# PAC52XX register map
Vendor: Active-Semi; Series: PAC52XX; File version: 1.0
CPU: CM0 r0p0, little endian, no MPU, no FPU, vendor SysTick, 2 interrupt priority bits
Registers are 32-bit, read-write, reset 0x0 unless marked. A register's access mark holds for its fields unless they carry their own. Offsets are from the block's base; [hi:lo] are bit positions; {n}, {i} and the like mark numbered series; 'fields as' and 'values as' point back to an identical list.

## ADC — Analog to Digital Converter
Base 0x40150000
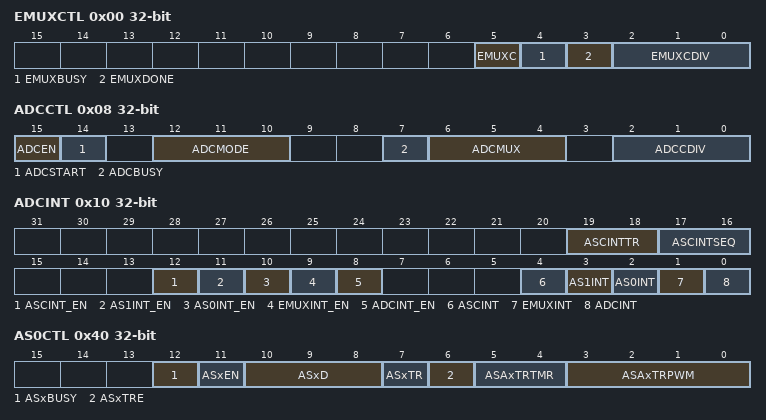
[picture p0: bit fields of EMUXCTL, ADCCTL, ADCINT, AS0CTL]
0x00 EMUXCTL — ADC External MUX control register
  [5] EMUXC — ADC External MUX control
    0=manual (ADC External MUX manual control); 1=auto (ADC External MUX controlled by auto-sequencer unit)
  [4] EMUXBUSY — ADC External MUX status
    0=busy (ADC External MUX busy); 1=not busy (ADC External MUX not busy)
  [3] EMUXDONE — ADC External MUX data send done
    0=busy (ADC External MUX busy); 1=data sent (ADC External MUX data sent)
  [2:0] EMUXCDIV — ADC External MUX clock to FCLK divider
    {v}=FCLK /{v+1} (FCLK dvided by {v+1}) (v=0..7)
0x04 EMUXDATA — ADC External MUX data register
  [15:0] DATA
0x08 ADCCTL — ADC control register
  [15] ADCEN — ADC Module Enable
    0=disabled (turn off ADC module); 1=enabled (enable ADC module)
  [14] ADCSTART — Start ADC Conversion
    0=stop ADC conversion; 1=start ADC conversion
  [12:10] ADCMODE — ADC conversion mode
    0=single channel; 1=AUTO0 (automated sequence 0 only); 2=AUTO1 (automated sequencer 1 only); 3=AUTO01 (automated sequencer 0 and 1 daisy chained); 4=AUTO0TRIG (automated sequencer 0 only trigger condition); 5=AUTO1TRIG (automated sequencer 1 only trigger condition); 6=AUTO01TRIG (automated sequencer 0 and 1 daisy chained trigger); 7=AUTO01TRIGIND (automated sequencer 0 and 1 independently triggered)
  [7] ADCBUSY ro
    0=no operation (ADC not busy); 1=busy (ADC conversion or auto sequencer active)
  [6:4] ADCMUX — ADC MUX input select
    0=AD0 (AD0 input); {v}=AD{v} (AD{v} input) (v=2..5); 7=VSSA (VSSA input)
  [2:0] ADCCDIV — ADC input clock FCLK divider
    {v}=FCLK /{v+1} (FCLK divided by {v+1}) (v=0..7)
0x0C ADCCR ro — ADC conversion result register
  [15:0] ADCRESULT — ADC conversion result
0x10 ADCINT — ADC interrupt register
  [19:18] ASCINTTR — Last auto sequencer to run
    0=none (no sequencer ran); 1=AS0 (auto sequencer 0 last ran); 2=AS1 (Auto sequencer 1 last ran)
  [17:16] ASCINTSEQ — Last auto sequencer to trigger ADCINT.ASCINT
    0=none (no trigger); 1=AS0 (auto sequencer 0 triggered interrupt); 2=AS1 (Auto sequencer 1 triggered interrupt); 3=Both auto sequencer 0 and 1 triggered interrupt
  [12] ASCINT_EN — Enable auto sequencer collision interrupt
    0=disabled (interrupt disabled); 1=enabled (interrupt enabled)
  [11] AS1INT_EN — Enable auto sequencer 1 conversions finished interrupt
    values as ASCINT_EN
  [10] AS0INT_EN — Enable auto sequencer 0 conversions finished interrupt
    values as ASCINT_EN
  [9] EMUXINT_EN — EMUX transfer finished interrupt enabled
    values as ASCINT_EN
  [8] ADCINT_EN — ADC conversion finished interrupt enabled
    values as ASCINT_EN
  [4] ASCINT — Auto sequencer collision interrupt
    0=none (no interrupt); 1=interrupt, write 1b to clear
  [3] AS1INT — Auto sequencer 1 conversions finished interrupt
    0=none (no interrupt); 1=interrupt, write 1b to clear
  [2] AS0INT — Auto sequencer 0 conversions finished interrupt
    0=none (no interrupt); 1=interrupt, write 1b to clear
  [1] EMUXINT — EMUX data transfer finished interrupt
    0=none (no interrupt); 1=interrupt, write 1b to clear
  [0] ADCINT — ADC conversion finished interrupt
    0=none (no interrupt); 1=interrupt, write 1b to clear
0x40 AS0CTL — Auto sequencer 0 control register
  [12] ASxBUSY — Auto sequencer busy
    0=not busy (auto sequencer not active); 1=busy (auto sequencer sampling active)
  [11] ASxEN — Auto sequencer enabled
    0=disabled (auto sequencer disabled); 1=enabled (auto sequencer enabled)
  [10:8] ASxD — Auto sequencer sampling depth
    0=1 sample; {v}={v+1} samples (v=1..7)
  [7] ASxTR — Auto sequencer trigger source
    0=PWM (PWM, as defined by ASxCTL.ASxTRPWM); 1=Timer, as defined by ASxCTL.ASxTRTMR
  [6] ASxTRE — Auto sequencer trigger source ASxCTL.ASxTR edge
    0=High to low edge; 1=Low to high edge
  [5:4] ASAxTRTMR — Auto sequencer timer trigger source
    0=Timer A; 1=Timer B; 2=Timer C; 3=Timer D
  [3:0] ASAxTRPWM — Auto sequencer PWM trigger source
    {v}=PWMA{v} (PWMA{v} Trigger) (v=0..7); 8=PWMB0; 9=PWMB1; 10=PWMC0; 11=PWMC1; 12=PWMD0; 13=PWMD1
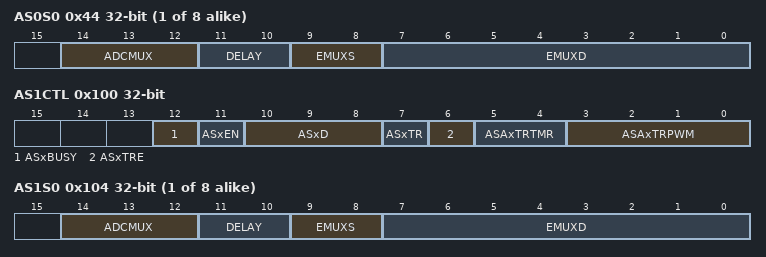
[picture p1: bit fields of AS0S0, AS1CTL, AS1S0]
{0x44+8i} AS0S{i} (i=0..7) — Auto sequencer 0 sample {i} control register
  [14:12] ADCMUX — ADC MUX input select
    0=EMUX; {v}=AD{v} (v=2..5); 7=VSSA
  [11:10] DELAY — Delay between start of sample sequence and start of ADC conversion in input clocks
    0=0 ADC input clocks; 1=4 ADC input clocks; 2=8 ADC input clocks; 3=16 ADC input clocks
  [9:8] EMUXS — EMUX transmission start
    0=none (Do not send data); 1=before (Send EMUXD data at beginning of this sample sequence); 2=end (Send EMUXD data after S/H of ADC)
  [7:0] EMUXD
0x48 AS0R0 — Auto sequencer 0 sample 0 result register
  [9:0] ADCRESULT — ADC conversion result
{0x48+8i} AS0R{i} (i=1..7) — Auto sequencer 0 sample {i} result register
0x100 AS1CTL — Auto sequencer 1 control register
  [12] ASxBUSY — Auto sequencer busy
    values as AS0CTL.ASxBUSY
  [11] ASxEN — Auto sequencer enabled
    values as AS0CTL.ASxEN
  [10:8] ASxD — Auto sequencer sampling depth
    0=1 sample; {v}={v+1} samples (v=1..7)
  [7] ASxTR — Auto sequencer trigger source
    values as AS0CTL.ASxTR
  [6] ASxTRE — Auto sequencer trigger source ASxCTL.ASxTR edge
    0=High to low edge; 1=Low to high edge
  [5:4] ASAxTRTMR — Auto sequencer timer trigger source
    0=Timer A; 1=Timer B; 2=Timer C; 3=Timer D
  [3:0] ASAxTRPWM — Auto sequencer PWM trigger source
    {v}=PWMA{v} (v=0..7); 8=PWMB0; 9=PWMB1; 10=PWMC0; 11=PWMC1; 12=PWMD0; 13=PWMD1
{0x104+8i} AS1S{i} (i=0..7) — Auto sequencer 1 sample {i} control register
  fields as AS0S0
0x108 AS1R0 — Auto sequencer 1 sample 0 result register
  [9:0] ADCRESULT — ADC conversion result
{0x108+8i} AS1R{i} (i=1..7) — Auto sequencer 1 sample {i} result register
